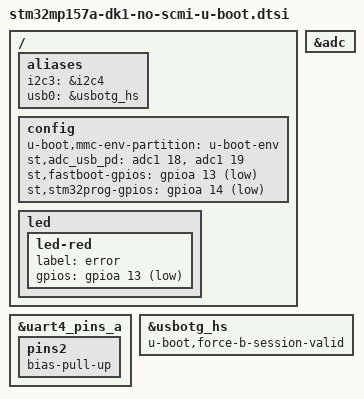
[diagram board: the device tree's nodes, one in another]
// SPDX-License-Identifier: GPL-2.0+ OR BSD-3-Clause
/*
 * Copyright : STMicroelectronics 2022
 */

#include "stm32mp15-u-boot.dtsi"

/ {
	aliases {
		i2c3 = &i2c4;
		usb0 = &usbotg_hs;
	};

	config {
		u-boot,mmc-env-partition = "u-boot-env";
		st,adc_usb_pd = <&adc1 18>, <&adc1 19>;
		st,fastboot-gpios = <&gpioa 13 (GPIO_ACTIVE_LOW | GPIO_PULL_UP)>;
		st,stm32prog-gpios = <&gpioa 14 (GPIO_ACTIVE_LOW | GPIO_PULL_UP)>;
	};

	led {
		led-red {
			label = "error";
			gpios = <&gpioa 13 GPIO_ACTIVE_LOW>;
		};
	};
};

&adc {
	status = "okay";
};

&uart4_pins_a {
	pins2 {
		/* pull-up on rx to avoid floating level */
		bias-pull-up;
	};
};

&usbotg_hs {
	u-boot,force-b-session-valid;
};
